# M365 register map
File version: 0.1
Registers are 32-bit, read-write, reset 0x0 unless marked. A register's access mark holds for its fields unless they carry their own. Offsets are from the block's base; [hi:lo] are bit positions; {n}, {i} and the like mark numbered series.

## AD — Analog-to-Digital Converter (AD)
Base 0x40050000
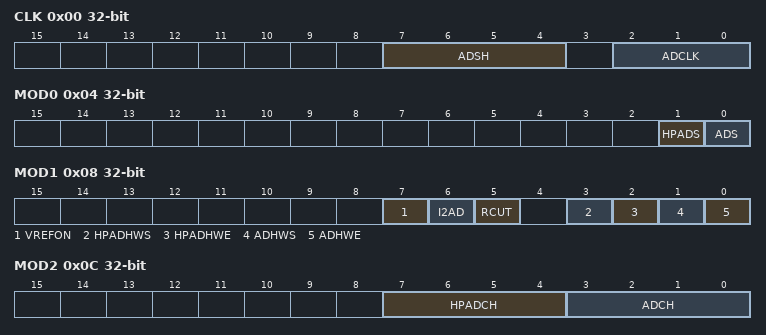
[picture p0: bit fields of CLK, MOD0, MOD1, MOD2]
0x00 CLK — AD Conversion Clock Setting Register
  [7:4] ADSH, [2:0] ADCLK
0x04 MOD0 wo — AD Mode Control Register 0
  [1] HPADS, [0] ADS
0x08 MOD1 — AD Mode Control Register 1
  [7] VREFON, [6] I2AD, [5] RCUT, [3] HPADHWS, [2] HPADHWE, [1] ADHWS, [0] ADHWE
0x0C MOD2 — AD Mode Control Register 2
  [7:4] HPADCH, [3:0] ADCH
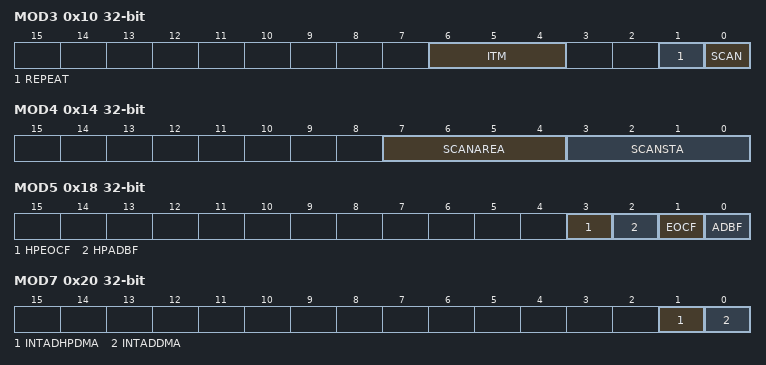
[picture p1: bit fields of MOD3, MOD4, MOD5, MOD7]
0x10 MOD3 — AD Mode Control Register 3
  [6:4] ITM, [1] REPEAT, [0] SCAN
0x14 MOD4 — AD Mode Control Register 4
  [7:4] SCANAREA, [3:0] SCANSTA
0x18 MOD5 ro — AD Mode Control Register 5
  [3] HPEOCF, [2] HPADBF, [1] EOCF, [0] ADBF
0x1C MOD6 wo — AD Mode Control Register 6
  [1:0] ADRST
0x20 MOD7 — AD Mode Control Register 7
  [1] INTADHPDMA, [0] INTADDMA
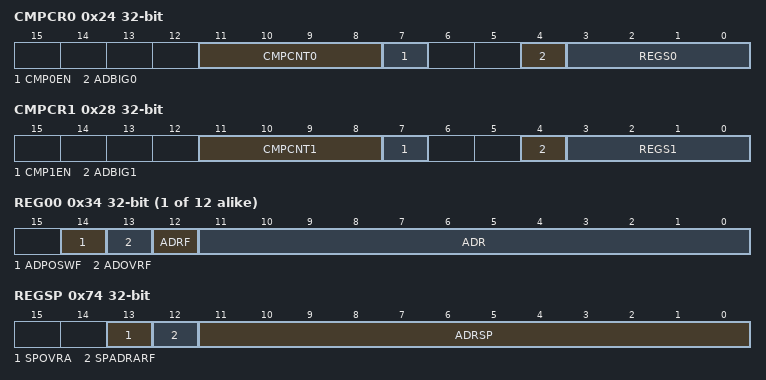
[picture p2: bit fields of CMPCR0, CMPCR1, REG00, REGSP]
0x24 CMPCR0 — AD Monitoring Setting Register 0
  [11:8] CMPCNT0, [7] CMP0EN, [4] ADBIG0, [3:0] REGS0
0x28 CMPCR1 — AD Monitoring Setting Register 1
  [11:8] CMPCNT1, [7] CMP1EN, [4] ADBIG1, [3:0] REGS1
0x2C CMP0 — AD Conversion Result Comparison Register 0
  [11:0] AD0CMP
0x30 CMP1 — AD Conversion Result Comparison Register 1
  [11:0] AD1CMP
{0x34+4i} REG{i:02} ro (i=0..11) — AD Conversion Result Register {i:02}
  [14] ADPOSWF, [13] ADOVRF, [12] ADRF, [11:0] ADR
0x74 REGSP ro — AD Conversion Result Register SP
  [13] SPOVRA, [12] SPADRARF, [11:0] ADRSP

## PA — General Purpose Input_Output Port (PA)
Base 0x400C0000
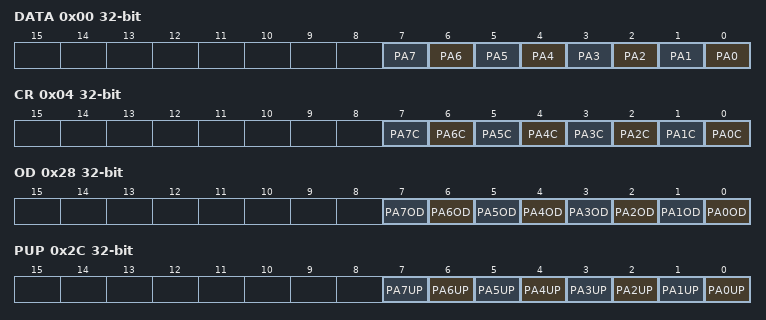
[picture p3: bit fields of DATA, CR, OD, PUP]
0x00 DATA — PA Data Register
  [n] PA{n} (n=0..7)
0x04 CR — PA Control Register
  [n] PA{n}C (n=0..7)
0x28 OD — PA Open Drain Control Register
  [n] PA{n}OD (n=0..7)
0x2C PUP — PA Pull-Up Control Register
  [n] PA{n}UP (n=0..7)
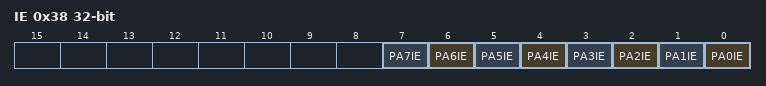
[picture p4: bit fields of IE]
0x38 IE — PA Input Enable Control Register
  [n] PA{n}IE (n=0..7)

## PB — General Purpose Input_Output Port (PB)
Base 0x400C0100
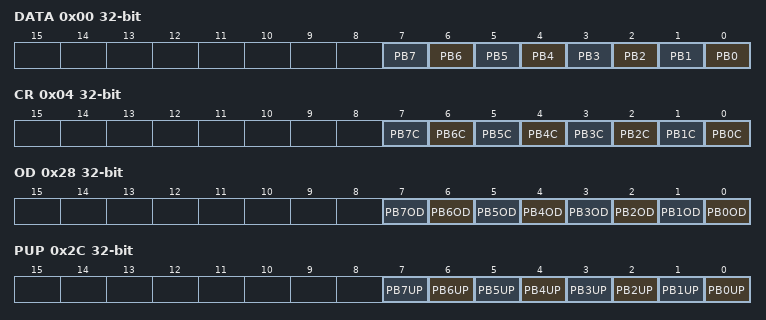
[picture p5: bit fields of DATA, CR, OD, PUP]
0x00 DATA — PB Data Register
  [n] PB{n} (n=0..7)
0x04 CR — PB Control Register
  [n] PB{n}C (n=0..7)
0x28 OD — PB Open Drain Control Register
  [n] PB{n}OD (n=0..7)
0x2C PUP — PB Pull-Up Control Register
  [n] PB{n}UP (n=0..7)
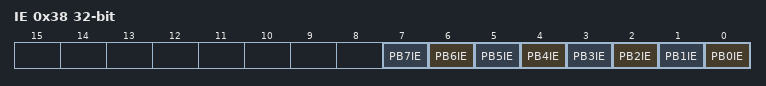
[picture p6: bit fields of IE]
0x38 IE — PB Input Enable Control Register
  [n] PB{n}IE (n=0..7)

## PC — General Purpose Input_Output Port (PC)
Base 0x400C0200
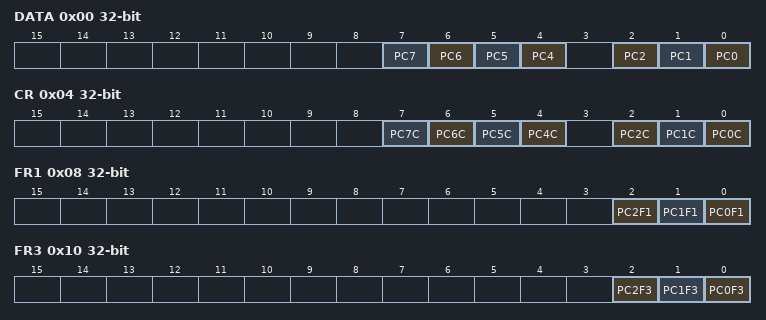
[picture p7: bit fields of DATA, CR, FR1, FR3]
0x00 DATA — PC Data Register
  [n] PC{n} (n=4..7), [2] PC2, [1] PC1, [0] PC0
0x04 CR — PC Control Register
  [n] PC{n}C (n=4..7), [2] PC2C, [1] PC1C, [0] PC0C
0x08 FR1 — PC Function Register 1
  [2] PC2F1, [1] PC1F1, [0] PC0F1
0x10 FR3 — PC Function Register 3
  [2] PC2F3, [1] PC1F3, [0] PC0F3
0x14 FR4 — PC Function Register 4
  [2] PC2F4
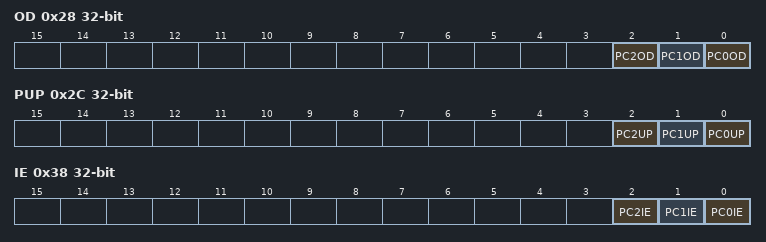
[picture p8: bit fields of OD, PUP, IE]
0x28 OD — PC Open Drain Control Register
  [2] PC2OD, [1] PC1OD, [0] PC0OD
0x2C PUP — PC Pull-Up Control Register
  [2] PC2UP, [1] PC1UP, [0] PC0UP
0x38 IE — PC Input Enable Control Register
  [2] PC2IE, [1] PC1IE, [0] PC0IE

## PD — General Purpose Input_Output Port (PD)
Base 0x400C0300
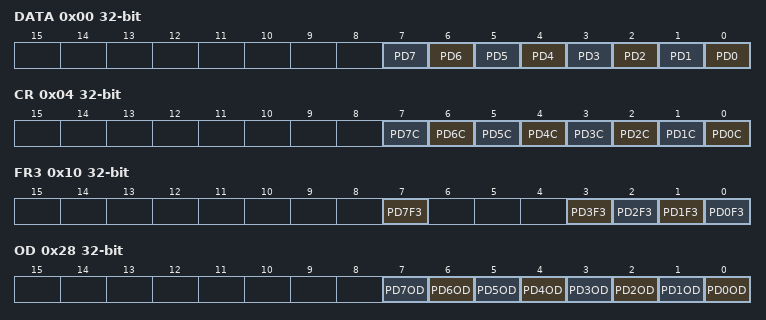
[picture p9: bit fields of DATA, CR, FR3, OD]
0x00 DATA — PD Data Register
  [n] PD{n} (n=0..7)
0x04 CR — PD Control Register
  [n] PD{n}C (n=0..7)
0x10 FR3 — PD Function Register 3
  [7] PD7F3, [n] PD{n}F3 (n=0..3)
0x28 OD — PD Open Drain Control Register
  [n] PD{n}OD (n=0..7)
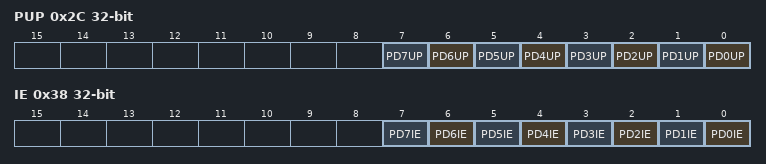
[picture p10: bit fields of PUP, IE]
0x2C PUP — PD Pull-Up Control Register
  [n] PD{n}UP (n=0..7)
0x38 IE — PD Input Enable Control Register
  [n] PD{n}IE (n=0..7)

## PE — General Purpose Input_Output Port (PE)
Base 0x400C0400
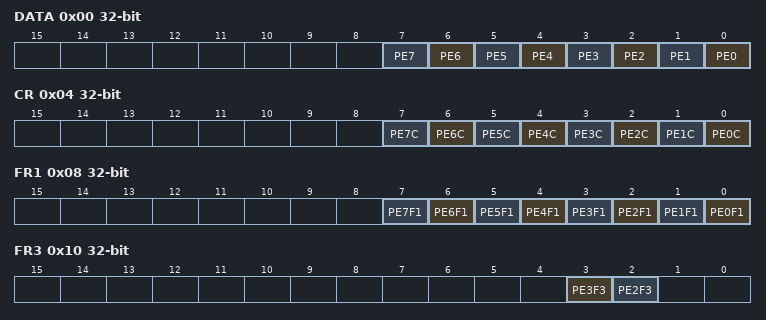
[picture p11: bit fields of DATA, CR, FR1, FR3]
0x00 DATA — PE Data Register
  [n] PE{n} (n=0..7)
0x04 CR — PE Control Register
  [n] PE{n}C (n=0..7)
0x08 FR1 — PE Function Register 1
  [n] PE{n}F1 (n=0..7)
0x10 FR3 — PE Function Register 3
  [3] PE3F3, [2] PE2F3
0x14 FR4 — PE Function Register 4
  [2] PE2F4
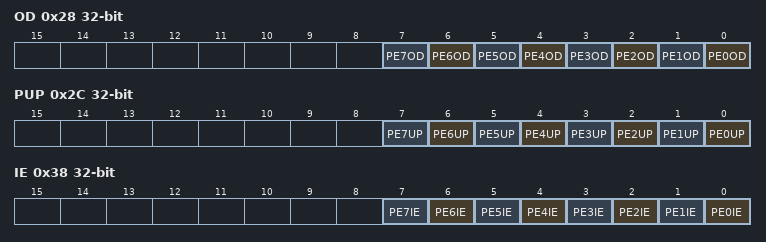
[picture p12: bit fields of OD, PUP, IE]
0x28 OD — PE Open Drain Control Register
  [n] PE{n}OD (n=0..7)
0x2C PUP — PE Pull-Up Control Register
  [n] PE{n}UP (n=0..7)
0x38 IE — PE Input Enable Control Register
  [n] PE{n}IE (n=0..7)

## PF — General Purpose Input_Output Port (PF)
Base 0x400C0500
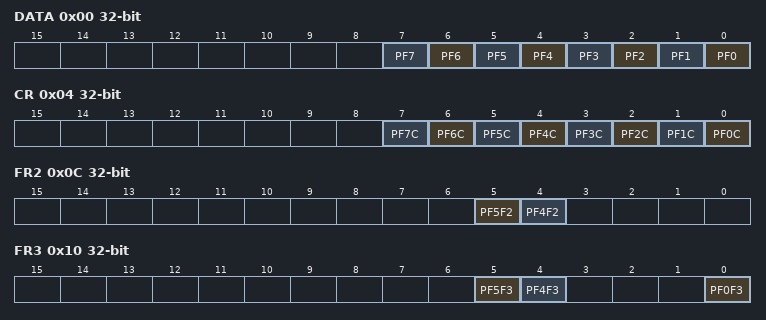
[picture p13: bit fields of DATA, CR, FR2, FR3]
0x00 DATA — PF Data Register
  [n] PF{n} (n=0..7)
0x04 CR — PF Control Register
  [n] PF{n}C (n=0..7)
0x0C FR2 — PF Function Register 2
  [5] PF5F2, [4] PF4F2
0x10 FR3 — PF Function Register 3
  [5] PF5F3, [4] PF4F3, [0] PF0F3
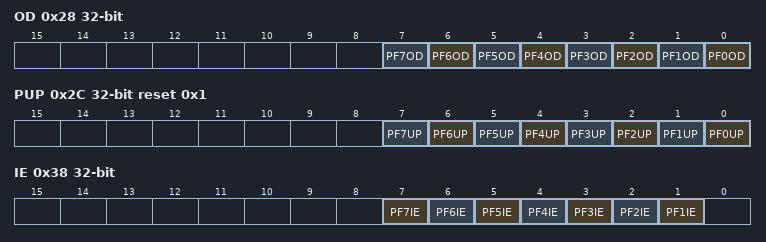
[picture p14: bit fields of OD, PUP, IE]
0x28 OD — PF Open Drain Control Register
  [n] PF{n}OD (n=0..7)
0x2C PUP reset 0x1 — PF Pull-Up Control Register
  [n] PF{n}UP (n=0..7)
0x38 IE — PF Input Enable Control Register
  [n] PF{n}IE (n=1..7)
